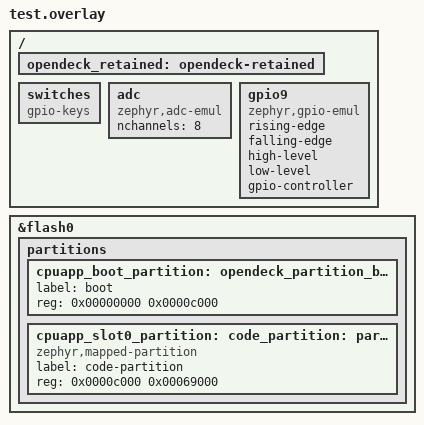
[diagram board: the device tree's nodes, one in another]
/ {
    opendeck_retained: opendeck-retained {
    };

    switches {
        compatible = "gpio-keys";
        status = "okay";
    };

    adc: adc {
        compatible = "zephyr,adc-emul";
        nchannels = <8>;
        #io-channel-cells = <1>;
        status = "okay";
    };

    gpio9: gpio9 {
        compatible = "zephyr,gpio-emul";
        rising-edge;
        falling-edge;
        high-level;
        low-level;
        gpio-controller;
        #gpio-cells = <2>;
        status = "okay";
    };
};

&flash0 {
    partitions {
        cpuapp_boot_partition: partition@0 {
            label = "boot";
            reg = <0x00000000 0x0000c000>;
        };

        cpuapp_slot0_partition: code_partition: partition@c000 {
            compatible = "zephyr,mapped-partition";
            label = "code-partition";
            reg = <0x0000c000 0x00069000>;
        };
    };
};

opendeck_partition_boot: &cpuapp_boot_partition {};

opendeck_partition_app: &cpuapp_slot0_partition {};
